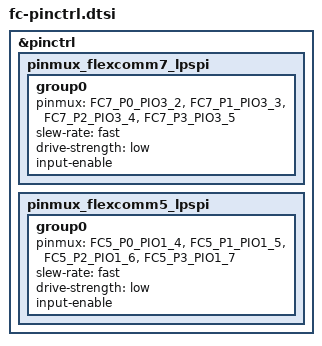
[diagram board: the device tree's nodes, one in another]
#include <nxp/mcx/MCXN947VDF-pinctrl.h>

&pinctrl {
	pinmux_flexcomm7_lpspi: pinmux_flexcomm7_lpspi {
		group0 {
			pinmux = <FC7_P0_PIO3_2>,
					 <FC7_P1_PIO3_3>,
					 <FC7_P2_PIO3_4>,
					 <FC7_P3_PIO3_5>;
			slew-rate = "fast";
			drive-strength = "low";
			input-enable;
		};
	};
	pinmux_flexcomm5_lpspi: pinmux_flexcomm5_lpspi {
		group0 {
			pinmux = <FC5_P0_PIO1_4>,
					 <FC5_P1_PIO1_5>,
					 <FC5_P2_PIO1_6>,
					 <FC5_P3_PIO1_7>;
			slew-rate = "fast";
			drive-strength = "low";
			input-enable;
		};
	};



};
